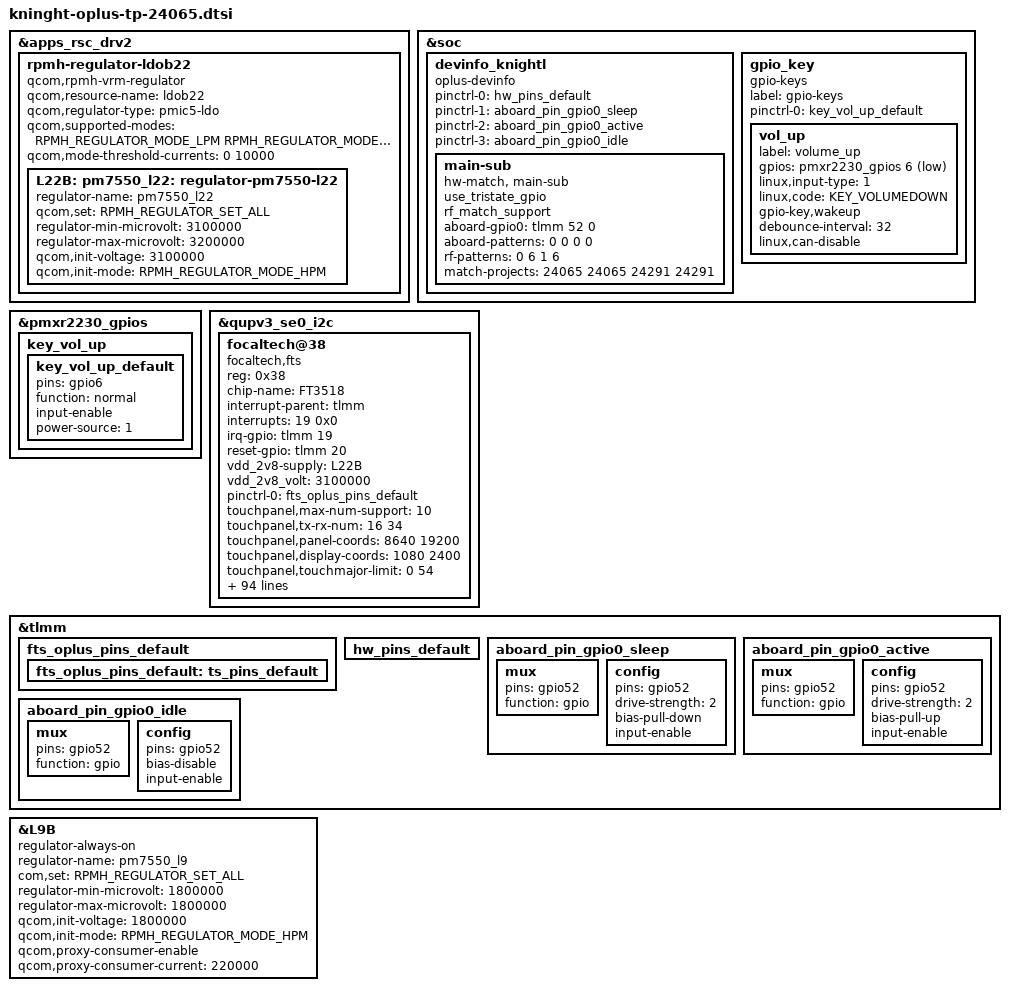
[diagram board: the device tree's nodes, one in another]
&apps_rsc_drv2 {
	rpmh-regulator-ldob22 {
		compatible = "qcom,rpmh-vrm-regulator";
		qcom,resource-name = "ldob22";
		qcom,regulator-type = "pmic5-ldo";
		qcom,supported-modes =
			<RPMH_REGULATOR_MODE_LPM
			RPMH_REGULATOR_MODE_HPM>;
		qcom,mode-threshold-currents = <0 10000>;

		L22B:
		pm7550_l22: regulator-pm7550-l22 {
			regulator-name = "pm7550_l22";
			qcom,set = <RPMH_REGULATOR_SET_ALL>;
			regulator-min-microvolt = <3100000>;
			regulator-max-microvolt = <3200000>;
			qcom,init-voltage = <3100000>;
			qcom,init-mode = <RPMH_REGULATOR_MODE_HPM>;
		};
	};
};

&soc {
	devinfo_knightl {
		compatible = "oplus-devinfo";
		pinctrl-names = "default", "sleep", "active", "idle";
		pinctrl-0 = <&hw_pins_default>;
		pinctrl-1 = <&aboard_pin_gpio0_sleep>;
		pinctrl-2 = <&aboard_pin_gpio0_active>;
		pinctrl-3 = <&aboard_pin_gpio0_idle>;

		main-sub {
			compatible = "hw-match, main-sub";
			use_tristate_gpio;
			rf_match_support;
			aboard-gpio0 = <&tlmm 52 0>;
			aboard-patterns = <0 0 0 0>;	/*0[high-resistance] 1[pull-down] 2[pull-up]*/
			/*rf value*/
			rf-patterns = <0 6 1 6>;	/*0[CN] 1[IN] 2[EU] 3[NA]*/
			/*main board*/
			match-projects = <24065 24065 24291 24291>;
		};
	};
};

&pmxr2230_gpios {
	/delete-node/ key_vol_up;
	key_vol_up {
		key_vol_up_default: key_vol_up_default {
			pins = "gpio6";
			function = "normal";
			input-enable;
			power-source = <1>;
		};
	};
};

&qupv3_se0_i2c {
	status = "ok";
	#address-cells = <1>;
	#size-cells = <0>;

	focaltech@38 {
		compatible = "focaltech,fts";
		reg = <0x38>;
		chip-name = "FT3518";
		status = "ok";

		/* Interrupt && Irq-gpio */
		interrupt-parent = <&tlmm>;
		interrupts = <19  0x0>;
		irq-gpio = <&tlmm 19 0x2002>;
		reset-gpio = <&tlmm 20 0x00>;

		/* Power Config */
		//enable2v8_gpio = <&tlmm 102 0x1>;
		//enable1v8_gpio = <&tlmm 97 0x1>;
		vdd_2v8-supply = <&L22B>;
		//vcc_1v8-supply = <&L9B>;
		vdd_2v8_volt = <3100000>;

		/* Other HW Resource */
		pinctrl-names = "default";
		pinctrl-0 = <&fts_oplus_pins_default>;

		touchpanel,max-num-support = <10>;
		touchpanel,tx-rx-num = <16 34>;
		touchpanel,panel-coords = <8640 19200>;
		touchpanel,display-coords = <1080 2400>;
		touchpanel,touchmajor-limit = <0 54>;
		touchpanel,report-rate = <120 180>;
		touchpanel,smooth-level = <255 2 15 25 45 60>;
		touchpanel,smooth-level-charging = <255 15 20 25 45 60>;
		touchpanel,sensitive-level = <255 20 17 14 10 8>;
		touchpanel,single-optimized-time = <8>;
		touchpanel,high-frame-rate-time = <20>;
		touchpanel,irq_need_dev_resume_time = <80>;

		panel_type = <8>;
		// type of tp_dev ,TP-SAMSUNG = 8;
		firmware_name = "0xAC116F00";
		platform_support_project = <24065 24291>;
		platform_support_project_dir = <24065 24065>;
		platform_support_project_commandline = "default_commandline","default_commandline";

		prevention,curved_screen_V2;
		prevention,grip_disable_level = <6>;
		prevention,updelay_time_ms = <30>;
		prevention,makeup_cnt_weight = <4 1 2 2 2>;
		prevention,large_corner_range = <960 2400>;
		prevention,large_corner_judge_condition = <500 300 800 7 7>;
		prevention,trx_reject_condition = <9 7 7>;
		prevention,trx_strict_reject_condition = <8 5 6>;
		prevention,large_judge_time_ms = <500 50 30>;
		prevention,large_exit_condition = <8 8 2>;
		prevention,single_channel_width = <160 160>;
		prevention,normal_tap_condition = <10 350>;
		prevention,long_edge_condition = <200 80 180 80>;
		prevention,long_strict_edge_condition = <160 60>;
		prevention,long_fingerhold_condition = <50 6 4 4>;
		prevention,short_edge_condition = <200 80 180 80>;
		prevention,short_strict_edge_condition = <160 60>;
		prevention,large_strict_exit_condition = <4 4>;
		prevention,top_corner_config = <440 1200 360>;
		prevention,edge_swipe_config = <240 960>;

		prevention,curved_screen_V4;
		prevention,long_eliminate_point_type = <2 8640 6400 240 19200 300 1>;
		prevention,long_fingerhold_condition2 = <420 0 0 0>;
		prevention,top_corner_config2 = <3 80 480 0 0>;
		prevention,hor_long_top_corner_config = <240 1600 0 0>;
		prevention,top_middle_config = <8640 800 800 0>;
		prevention,corner_eliminate_point_type = <0 960 1600 1>;
		prevention,finger_hold_differ_size = <1 0 240 300>;
		prevention,finger_hold_max_rx_exit_distance = <5 240 1600>;
		prevention,max_rx_exit_distance = <1 5 150 240 1600>;
		prevention,dynamic_finger_hold_exit_distance = <1 240 1600 360>;
		prevention,edge_sliding_matched_support = <1 150 3 0>;

		/* //grip v4.2 reclining mode
		prevention,reclining_mode_support = <1>;
		prevention,long_eliminate_point_type_recli = <2 8640 6400 80 19200 500 0>;
		prevention,finger_hold_differ_size_recli = <1 0 108 400>;
		prevention,finger_hold_max_rx_exit_distance_recli = <4 60 380>;
		prevention,max_rx_exit_distance_recli = <1 4 100 60 350>;
		prevention,dynamic_finger_hold_exit_distance_recli = <1 60 380 140>;
		prevention,edge_sliding_matched_support_recli = <1 200 3 0>; */
		/*for grip 4.3*/
		prevention,curved_screen_v4_3;
		prevention,corner_point_edge_percent_thd = <1600 1 30 32 1>;
		prevention,corner_point_edge_percent_thd2 = <40 3 20 0 0>;
		prevention,point_stability_judgment_check = <1 1 0 0 0>;
		prevention,point_corner_er_min_limit_check = <3 3 0 0 1>;
		prevention,one_frame_down_check_support = <1>;

		/* SW Support Feature Control */
		black_gesture_support;
		black_gesture_indep_support;
		sportify_aod_gesture_support;
		pressure_report_support;
		charger_pump_support;
		game_switch_support;
		smart_gesture_support;
		fw_update_app_support;
		fingerprint_underscreen_support;
		freq_hop_simulate_support;
		screenoff_fingerprint_info_support;
		irq_need_dev_resume_ok;
		kernel_grip_support;
		//fw_edge_limit_support;
		exception_upload_support;
		health_monitor_support;
		//focalt x8 resolution config
		high_resolution_support;
		high_resolution_support_x8;
		disable_suspend_irq_handler_support;
		headset_pump_support;
		snr_read_support;
		palm_to_sleep_support;
		temperature_detect_shellback_support;
		fingerprint_not_report_in_suspend;
		glove_mode_v2_support;
		disable_touch_event_support;
		fp_unlock_status_support;
		/*
		  *Virtual Key Config:
		  *1:touchpanel,button-type: <virtualkey_type  supportted_button-map>
		  *virtualkey_type:
		  *Type 1: using board_properties
		  *Type 2: using same IC (button zone&& touch zone are seprate)
		  *Type 3: using diffrent IC (button zone&& touch zone are seprate)
		  *Type 4: No need of virtual key process
		  *supportted_button-map:select|menu|home|back
		  *
		  *2:touchpanel,button-map
		  *type (X1,Y1)(X2,Y2)(X3,Y3)(Width_X,Hight_Y)--Only when button-type is 0
		*/
		touchpanel,button-type = <4>;
		touchpanel.button-TRx = <0 0>;
	};
};

&tlmm {
	fts_oplus_pins_default {
		fts_oplus_pins_default: ts_pins_default {
		};
	};

	hw_pins_default:hw_pins_default {
	};

	aboard_pin_gpio0_sleep:aboard_pin_gpio0_sleep {
		mux {
			pins = "gpio52";
			function = "gpio";
		};
		config {
			pins = "gpio52";
			drive-strength = <2>;
			bias-pull-down;
			input-enable;
		};
	};

	aboard_pin_gpio0_active:aboard_pin_gpio0_active {
		mux {
			pins = "gpio52";
			function = "gpio";
		};
		config {
			pins = "gpio52";
			drive-strength = <2>;
			bias-pull-up;
			input-enable;
		};
	};

	aboard_pin_gpio0_idle:aboard_pin_gpio0_idle {
		mux {
			pins = "gpio52";
			function = "gpio";
		};
		config {
			pins = "gpio52";
			bias-disable;
			input-enable;
		};
	};
};

&soc {
	/delete-node/ gpio_key;
	gpio_key {
		compatible = "gpio-keys";
		label = "gpio-keys";
		pinctrl-names = "default";
		pinctrl-0 = <&key_vol_up_default>;
		vol_up {
			label = "volume_up";
			gpios = <&pmxr2230_gpios 6 GPIO_ACTIVE_LOW>;
			linux,input-type = <1>;
			linux,code = <KEY_VOLUMEDOWN>;
			gpio-key,wakeup;
			debounce-interval = <32>;
			linux,can-disable;
		};
	};
};

&L9B {
	regulator-always-on;
	regulator-name = "pm7550_l9";
	com,set = <RPMH_REGULATOR_SET_ALL>;
	regulator-min-microvolt = <1800000>;
	regulator-max-microvolt = <1800000>;
	qcom,init-voltage = <1800000>;
	qcom,init-mode = <RPMH_REGULATOR_MODE_HPM>;
	qcom,proxy-consumer-enable;
	qcom,proxy-consumer-current = <220000>;
};

